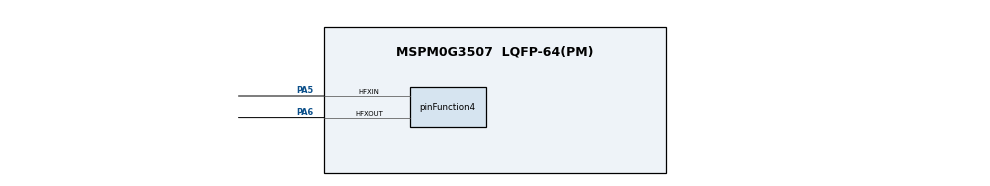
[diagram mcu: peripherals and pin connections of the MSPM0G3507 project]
/**
 * AI AGENTS: Do not edit this file directly. There is no validation or error feedback when
 * editing manually — mistakes will be silent until the file is loaded in SysConfig.
 * Use the SysConfig MCP server instead to make changes with immediate error reporting.
 *
 * These arguments were used when this file was generated. They will be automatically applied on subsequent loads
 * via the GUI or CLI. Run CLI with '--help' for additional information on how to override these arguments.
 * @cliArgs --device "MSPM0G350X" --part "Default" --package "LQFP-64(PM)" --product "mspm0_sdk@2.10.00.04"
 * @v2CliArgs --device "MSPM0G3507" --package "LQFP-64(PM)" --product "mspm0_sdk@2.10.00.04"
 * @versions {"tool":"1.28.0+4712"}
 */

/**
 * Import the modules used in this configuration.
 */
const SYSCTL        = scripting.addModule("/ti/driverlib/SYSCTL");
const SYSTICK       = scripting.addModule("/ti/driverlib/SYSTICK");
const ProjectConfig = scripting.addModule("/ti/project_config/ProjectConfig");

/**
 * Write custom configuration values to the imported modules.
 */
const divider9       = system.clockTree["UDIV"];
divider9.divideValue = 2;

const mux2       = system.clockTree["CANCLKMUX"];
mux2.inputSelect = "CANCLKMUX_PLLCLK1_OUT";

const mux4       = system.clockTree["EXHFMUX"];
mux4.inputSelect = "EXHFMUX_XTAL";

const mux8       = system.clockTree["HSCLKMUX"];
mux8.inputSelect = "HSCLKMUX_SYSPLL2X";

const mux10       = system.clockTree["MFPCLKMUX"];
mux10.inputSelect = "MFPCLKMUX_HFCLK";

const mux12       = system.clockTree["SYSPLLMUX"];
mux12.inputSelect = "zSYSPLLMUX_HFCLK";

const pinFunction4                        = system.clockTree["HFXT"];
pinFunction4.inputFreq                    = 40;
pinFunction4.enable                       = true;
pinFunction4.HFXTStartup                  = 10;
pinFunction4.peripheral.hfxInPin.$assign  = "PA5";
pinFunction4.peripheral.hfxOutPin.$assign = "PA6";

SYSCTL.clockTreeEn           = true;
SYSCTL.forceDefaultClkConfig = true;

const Board = scripting.addModule("/ti/driverlib/Board", {}, false);

SYSTICK.periodEnable    = true;
SYSTICK.period          = 80000;
SYSTICK.interruptEnable = true;
SYSTICK.systickEnable   = true;

ProjectConfig.genLibCMSIS = true;
ProjectConfig.compiler    = "gcc";

/**
 * Pinmux solution for unlocked pins/peripherals. This ensures that minor changes to the automatic solver in a future
 * version of the tool will not impact the pinmux you originally saw.  These lines can be completely deleted in order to
 * re-solve from scratch.
 */
pinFunction4.peripheral.$suggestSolution   = "SYSCTL";
Board.peripheral.$suggestSolution          = "DEBUGSS";
Board.peripheral.swclkPin.$suggestSolution = "PA20";
Board.peripheral.swdioPin.$suggestSolution = "PA19";
